# psoc4200bl register map
Vendor: Cypress Semiconductor; Series: PSoC4200BL; File version: 1.0
CPU: CM0 r0p1, little endian, no MPU, no FPU, 2 interrupt priority bits
Registers are 32-bit, read-write, reset 0x0 unless marked. A register's access mark holds for its fields unless they carry their own. Offsets are from the block's base; [hi:lo] are bit positions; lines under a group give offsets from that group; {n}, {i} and the like mark numbered series; <NAME> marks a mode.

## BLE (part 4 of 5) — Bluetooth Low Energy Subsystem
Base 0x402E0000
0x1000 BLELL group — Bluetooth Low Energy Link Layer
  0x120 NEXT_CE_INSTANT ro — Next connection event instant
    [15:0] NEXT_CE_INSTANT — 16-bit internal reference clock value at which the next connection event will occur on a connection. The connection index register must be programmed with index of the connection, before reading the register.
  0x124 CONN_CE_COUNTER ro — connection event counter
    [15:0] CONNECTION_EVENT_COUNTER — This is the free running counter, connEventCounter as defined by Bluetooth spec. Firmware will read the instantaneous Event counter from this register, during connection update and channel map update procedure. Firmware will use this value to calculate the instant from which the new parameters (for connection update and channel map update) will be effective.
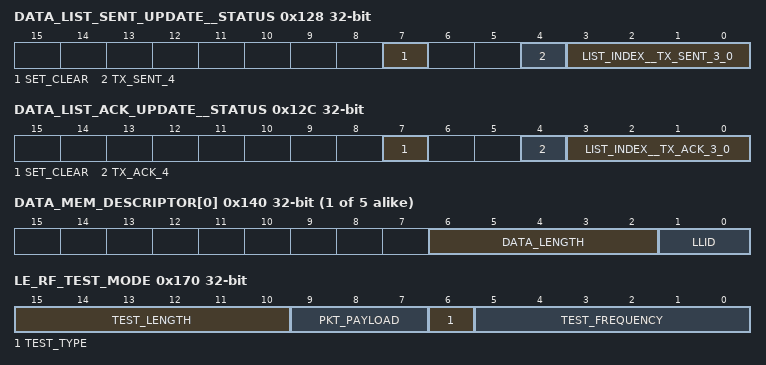
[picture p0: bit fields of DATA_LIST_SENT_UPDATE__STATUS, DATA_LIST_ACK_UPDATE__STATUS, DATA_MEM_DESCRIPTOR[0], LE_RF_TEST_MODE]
  0x128 DATA_LIST_SENT_UPDATE__STATUS — data list sent update and status
    [7] SET_CLEAR wo — Write: Used to set the SENT bit in hardware for the selected packet buffer. 1 - packet queued When firmware has a packet to send, firmware first loads the next available packet buffer. Then the hardware SENT bit is set by writing 1 to this bit field along with the list_index field that identified the buffer index. This indicates that a packet has been queued in the data buffer for sending. This packet is now ready to be transmitted. The SENT bit in hardware is cleared by hardware only when it has received an acknowledgement from the remote device. Firmware typically does not clear the bit. However, It only clears the bit on its own if it needs to 'flush' a packet from the buffer, without waiting to receive acknowledgement from the remote device, firmware clears BIT7 along with the list_index specified.
    [4] TX_SENT_4 ro — Read: Reads TX_SENT[4]. The bits in this field indicate the status of the SENT bit in the hard-ware for each packet buffer. The bit values are 1 - queued 0 - no packet / packet ack received by hardware Example1: If the read value is : 0x03, then packets in buffer 0 and buffer 1 are in the queue to be transmitted. All the other FIFOs are empty or hardware has cleared them after receiving acknowledgement. NOTE: The SENT status bit and ACK status bit have to be taken together to understand the meaning of packet status. The table below describes how the two bits are sequentially updated by either hardware/firmware to complete one data transmission. SENT ACK Description 0 0 Buffer is empty. No packet is queued in the buffer 1 0 Packet is queued by firmware. 1 1 Packet is transmitted by hardware. Hardware is waiting for acknowledgement. 0 1 Hardware has received ACK. Firmware has not yet processed the ACK. 0 0 Firmware has processed the ack. The buffer is again empty.
    [3:0] LIST_INDEX__TX_SENT_3_0 — Write:Indicates the buffer index for which the SENT bit is being updated by firmware. The default number of buffers in the IP is 5. The index range is 0-4. Read: Reads TX_SENT[3:0]. The bits in this field indicate the status of the SENT bit in the hard-ware for each packet buffer. The bit values are 1 - queued 0 - no packet / packet ack received by hardware Example1: If the read value is : 0x03, then packets in buffer 0 and buffer 1 are in the queue to be transmitted. All the other FIFOs are empty or hardware has cleared them after receiving acknowledgement.
  0x12C DATA_LIST_ACK_UPDATE__STATUS — data list ack update and status
    [7] SET_CLEAR wo — Write: Firmware uses the field to clear and ACK bit in the hardware to indicate that the acknowledgement for the transmit packet has been received and processed by firmware. Firmware clears the ACK bit in the hardware by writing in this register only after the acknowledgement is processed successfully by firmware. For clearing ack for a packet transmitted in fifo-index : '3', firm-ware will write '3' in the 'list-index' field and set this bit (BIT7) to 0. This is the indication that the corresponding packet buffer identi-fied by List-Index is cleared of previous transmission and can be re-used for another packet from now on. The ACK bit in hardware is set by hardware when it has success-fully transmitted a packet.
    [4] TX_ACK_4 ro — Reads TX_ACK[4] If a particular bit is set, then the packet in the selected buffer has been transmitted (at least once) by the hardware and hardware is waiting for acknowledgement. Example1 : If the read value is : 0x03, then packets in FIFO-0 and FIFO-1 are acknowledged by the remote device. These acknowledgements are pending to be processed by firmware. Example2 : If the read value is : 0x02, then packet FIFO-1 is acknowledged by the remote device. This acknowledgement is pending to be processed by firmware. NOTE: The SENT status bit and ACK status bit have to be taken together to understand the meaning of packet status. The table below describes how the two bits are sequentially updated by either hardware/firmware to complete one data transmission. SENT ACK Description 0 0 Buffer is empty. No packet is queued in the buffer 1 0 Packet is queued by firmware. 1 1 Packet is transmitted by hardware. Hardware is waiting for acknowledgement. 0 1 Hardware has received ACK. Firmware has not yet processed the ACK. 0 0 Firmware has processed the ack. The buffer is again empty.
    [3:0] LIST_INDEX__TX_ACK_3_0 — Write: Indicates the buffer index for which the ACK bit is being updated by firmware. The default number of buffers in the IP is 5. The index range is 0-4. Read: Reads TX_ACK[3:0] If a particular bit is set, then the packet in the selected buffer has been transmitted (at least once) by the hardware and hardware is waiting for acknowledgement. Example1 : If the read value is : 0x03, then packets in FIFO-0 and FIFO-1 are acknowledged by the remote device. These acknowledgements are pending to be processed by firmware. Example2 : If the read value is : 0x02, then packet FIFO-1 is acknowledged by the remote device. This acknowledgement is pending to be processed by firmware.
  {0x140+4j} DATA_MEM_DESCRIPTOR[{j}] (j=0..4) — Data buffer descriptor 0 to 4
    [6:2] DATA_LENGTH — This field indicates the length of the data packet. Range 0x0 to 0xF.
    [1:0] LLID
  0x160 WINDOW_WIDEN_INTVL reset 0xA — Window widen for interval
    [11:0] WINDOW_WIDEN_INTVL — This value defines the increased listening time for the slave. The window widening shall be smaller than ((connInterval/2)-T_IFS us) This value is calculated by firmware based on the drift, the connec-tion interval value. The value is the unit widening value for one con-nection interval duration. In case of slave latency, this value is accu-mulated till the next anchor point at which the slave will listen.
  0x164 WINDOW_WIDEN_WINOFF reset 0xA — Window widen for offset
    [11:0] WINDOW_WIDEN_WINOFF — This field stores the additional number of microseconds the slave must extend its listening window to listen for a master packet. This value is calculated based on the window offset value. This is used at connection setup directly. During connection setup, this value is added with window_widen_intvl register value to calculate the win-dow widening size.
  0x170 LE_RF_TEST_MODE — Direct Test Mode control
    [15:10] TEST_LENGTH
    [9:7] PKT_PAYLOAD
    [6] TEST_TYPE — 1 - DTM test ON 0 - DTM test OFF
    [5:0] TEST_FREQUENCY — N = (F - 2402) / 2 Range: 0x00 - 0x27. Frequency Range : 2402 MHz to 2480 MHz
  0x174 DTM_RX_PKT_COUNT ro — Direct Test Mode receive packet count
    [15:0] RX_PACKET_COUNT — Number of packets received in receive test mode.
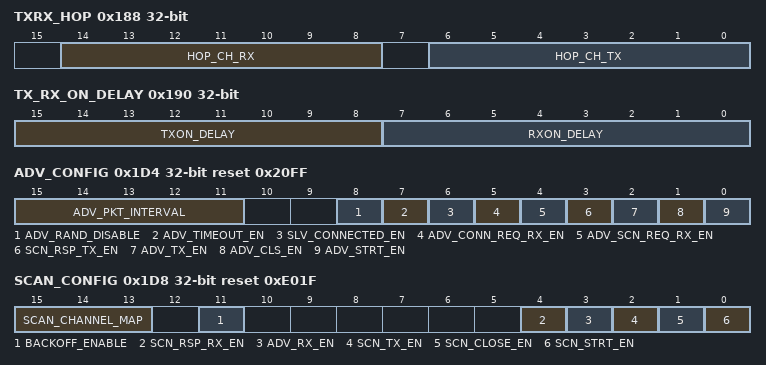
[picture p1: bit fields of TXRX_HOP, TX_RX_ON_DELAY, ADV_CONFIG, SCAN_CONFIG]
  0x188 TXRX_HOP ro — Channel Address register
    [14:8] HOP_CH_RX — Receive channel index. Channel index on which previous packet is received.
    [6:0] HOP_CH_TX — Transmit channel index. Channel index on which previous packet is transmitted.
  0x190 TX_RX_ON_DELAY — Transmit/Receive data delay
    [15:8] TXON_DELAY — Transmit delay - Delay from start of transmit to transmission of first bit on air. It is used to control the T_IFS. The delay is in resolution of 1 microsecond.
    [7:0] RXON_DELAY — Receive delay - Delay from start of receive to expected first bit of receive packet at the controller. Used to control the turn on time of radio to optimize on power. The delay is in resolution of 1 microsecond.
  0x1C0 DEV_PUB_ADDR_L reset 0x3412 — Device public address lower register
    [15:0] DEV_PUB_ADDR_L — Lower 16 bit of 48-bit public address of the device.
  0x1C4 DEV_PUB_ADDR_M reset 0x56 — Device public address middle register
    [15:0] DEV_PUB_ADDR_M — Middle 16 bit of 48-bit public address of the device.
  0x1C8 DEV_PUB_ADDR_H — Device public address higher register
    [15:0] DEV_PUB_ADDR_H — Higher 16 bit of 48-bit public address of the device.
  0x1CC ADV_CH_TX_POWER reset 0x874F — Advetising channel transmit power
    [15:0] ADV_TRANSMIT_POWER — Size: 1 Octet (signed integer) Range: -20 <= N <= 10 Units: dBm Accuracy: +/- 4 dBm in general. In implementation this is a radio specific value.
  0x1D0 OFFSET_TO_FIRST_INSTANT reset 0x6
    [15:0] OFFSET_TO_FIRST_EVENT — The offset w.r.t the internal reference clock at which instant the first event occurs. This register will give flexibility to the firmware to position the con-nection at a desired point with respect to the internal free running clock. It is optional to be updated by firmware. This is not updated in the current firmware.
  0x1D4 ADV_CONFIG reset 0x20FF — Advertiser configuration register
    [15:11] ADV_PKT_INTERVAL — Time between the beginning of two consecutive advertising PDU's. Time = N * 0.625 msec Time Range: <=10msec.
    [8] ADV_RAND_DISABLE — Disable randomization of adv interval. When disabled, interval is same as programmed in adv_interval register.
    [7] ADV_TIMEOUT_EN — Enable adv_timeout interrupt. Applicable in adv_direct_ind advertising.
    [6] SLV_CONNECTED_EN — Enable slave connected interrupt.
    [5] ADV_CONN_REQ_RX_EN — Enable connect request packet received interrupt.
    [4] ADV_SCN_REQ_RX_EN — Enable scan request packet received interrupt.
    [3] SCN_RSP_TX_EN — Enable scan response packet transmitted interrupt.
    [2] ADV_TX_EN — Enable adv packet transmitted interrupt.
    [1] ADV_CLS_EN — Enable advertising event stop interrupt.
    [0] ADV_STRT_EN — Enable advertising event start interrupt.
  0x1D8 SCAN_CONFIG reset 0xE01F — Scan configuration register
    [15:13] SCAN_CHANNEL_MAP — Advertising channels that are enabled for scanning operation. Bit 15: setting 1 - enables channel 39 for use. Bit 14: setting 1 - enables channel 38 for use. Bit 13: setting 1 - enables channel 37 for use.
    [11] BACKOFF_ENABLE — Enable random backoff feature in scanner. 1 - enable 0 - disable
    [4] SCN_RSP_RX_EN — Enable scan_rsp packet received interrupt .
    [3] ADV_RX_EN — Enable adv packet received interrupt .
    [2] SCN_TX_EN — Enable scan request packet transmitted interrupt.
    [1] SCN_CLOSE_EN — Enable scan event close interrupt.
    [0] SCN_STRT_EN — Enable scan event start interrupt.
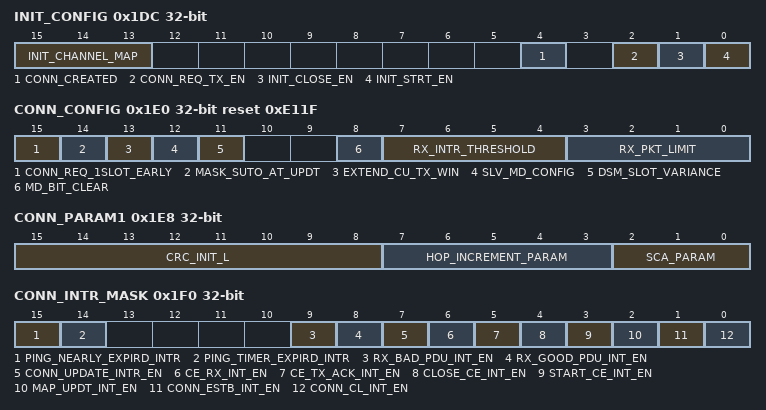
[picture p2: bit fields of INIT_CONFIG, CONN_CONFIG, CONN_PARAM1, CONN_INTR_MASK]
  0x1DC INIT_CONFIG — Initiator configuration register
    [15:13] INIT_CHANNEL_MAP — Advertising channels that are enabled for initiator scanning operation. Bit 15: setting 1 - enables channel 39 for use. Bit 14: setting 1 - enables channel 38 for use. Bit 13: setting 1 - enables channel 37 for use.
    [4] CONN_CREATED — Enable master connection created interrupt
    [2] CONN_REQ_TX_EN — Enables connection request packet transmission start interrupt.
    [1] INIT_CLOSE_EN — Enable Initiator event close interrupt.
    [0] INIT_STRT_EN — Enable Initiator event start interrupt.
  0x1E0 CONN_CONFIG reset 0xE11F — Connection configuration register
    [15] CONN_REQ_1SLOT_EARLY — This bit is used to enable extension of the Conn Request to arbiter to 1 slot early. When enabled the request length is 2 slots. 1 - Enable 0 - Disable
    [14] MASK_SUTO_AT_UPDT — This bit is used to enable/disable masking of internal hardware supervision timeout trigger when switching from old connection parameters to new parameters. 1 - Enable 0 - Disable
    [13] EXTEND_CU_TX_WIN — This bit is used to enable/disable extending the additional rx window on slave side during connection update in event of packet miss at the update instant. 1 - Enable 0 - Disable
    [12] SLV_MD_CONFIG — This bit is set to configure the MD bit control when IUT is in slave role. 1 - MD bit will be decided on packet pending status 0 - MD bit will be decided on packet queued in next buffer status This bit has effect only when 'CONN_CONFIG.md_bit_ctr' bit is not set .
    [11] DSM_SLOT_VARIANCE — This bit configures the DSM slot counting mode. 0 - The DSM slot count variance with respect to actual time is less than 1 slot 1 - The DSM slot count variance with respect to actual time is more than 1 slot &less that 2 slots
    [8] MD_BIT_CLEAR — This register field indicates whether the MD (More Data) bit needs to be controlled by 'software' or, 'hardware and soft-ware logic combined'. 1 - MD bit is exclusively controlled by software, ie based on status of CE_CNFG_STS_REGISTER[6] - md bit. 0 - MD Bit in the transmitted pdu is controlled by software and hardware logic. MD bit is set in transmitted packet, only if the software has set the md bit in CE_CNFG_STS_REGISTER[6] and either of the following conditions is true, a) If there are packets queued for transmission. b) If there is an acknowledgement awaited from the remote side for the packet transmitted.
    [7:4] RX_INTR_THRESHOLD — This register field allows setting a threshold for the packet received interrupt to the firmware. For example if the value programmed is 0x2 - then HW will generate interrupt only on receiving the second packet. In any case if the received number of packets in a conn event is less than the threshold or there are still packets (less than threshold) pending in the Rx FIFO, HW will generate the interrupt at the ce_close. Min value possible is 1. Max value depends on the Rx FIFO capacity.
    [3:0] RX_PKT_LIMIT — Defines a limit for the number of Rx packets that can be re-ceived by the LLH. Default maximum value is 0xF.Minimum value shall be '1' or no packet will be stored in the Rx FIFO.
  0x1E4 CONN_CH_TX_POWER — Connection channel transmit power
    [15:0] CONNCH_TRANSMIT_POWER — Transmit power to be used for all packets transmitted on the connection channel.
  0x1E8 CONN_PARAM1 — Connection parameter 1
    [15:8] CRC_INIT_L — This field defines the lower byte (7:0) of the CRC initialization vector.
    [7:3] HOP_INCREMENT_PARAM — Hop increment for connection channel.
    [2:0] SCA_PARAM — Sleep Clock Accuracy
  0x1EC CONN_PARAM2 — Connection parameter 2
    [15:0] CRC_INIT_H — This field defines the upper two bytes (23:8) of the CRC initialization vector.
  0x1F0 CONN_INTR_MASK — Connection Interrupt mask
    [15] PING_NEARLY_EXPIRD_INTR — If this bit is set ping timer nearly expired interrupt is enabled
    [14] PING_TIMER_EXPIRD_INTR — If this bit is set ping timer expired interrupt is enabled.
    [9] RX_BAD_PDU_INT_EN — If this bit is set packet receive bad pdu interrupt is enabled. Effective only when bit 6 is set.
    [8] RX_GOOD_PDU_INT_EN — If this bit is set packet receive good pdu interrupt is enabled. Effective only when bit 6 is set.
    [7] CONN_UPDATE_INTR_EN — If this bit is set connection update interrupt is enabled.
    [6] CE_RX_INT_EN — If this bit is set interrupt is enabled for reception of packet in a connection event.
    [5] CE_TX_ACK_INT_EN — If this bit is set transmission acknowledgement interrupt is enabled: This interrupt is generated to indicate to the firmware that a non-empty packet transmitted is successfully acknowledged by the remote device. For negative acknowledgements from remote device, this interrupt indication is not generated.
    [4] CLOSE_CE_INT_EN — If this bit is set connection event closed interrupt is enabled.
    [3] START_CE_INT_EN — If this bit is set connection event start interrupt is enabled
    [2] MAP_UPDT_INT_EN — If this bit is set, channel map update interrupt is enabled.
    [1] CONN_ESTB_INT_EN — If this bit is set connection establishment interrupt is enabled.
    [0] CONN_CL_INT_EN — If this bit is set connection closed interrupt is enabled.
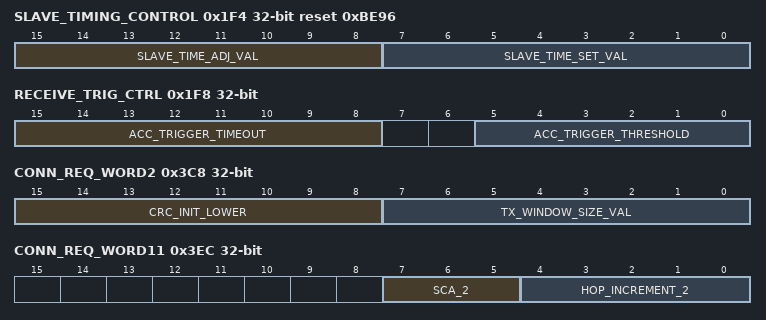
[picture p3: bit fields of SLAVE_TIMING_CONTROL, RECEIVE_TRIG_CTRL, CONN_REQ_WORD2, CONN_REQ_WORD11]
  0x1F4 SLAVE_TIMING_CONTROL reset 0xBE96
    [15:8] SLAVE_TIME_ADJ_VAL — Timing adjust value. The internal micro second counter is adjusted to this value whenever slave receives a good access address match at connection anchor point. This will ensure the slave gets synchronized to master timing.
    [7:0] SLAVE_TIME_SET_VAL — Programmable adjust value to the clock counter when slave is connected
  0x1F8 RECEIVE_TRIG_CTRL — Receive trigger control
    [15:8] ACC_TRIGGER_TIMEOUT — If access address match does not occur then within this time from the start of receive operation, the receive operation times out and stops. An internal counter value of 1usec resolution is continuously compared with the value programmed. Max value :0xFF
    [5:0] ACC_TRIGGER_THRESHOLD — Access address match threshold value. Number of bits of ac-cess address that should match with the expected access ad-dress to trigger an access code match. Max value : 32 (for 32-bit access address) Lower values may be programmed for bad radios or channels but care must be taken to ensure there are no 'false' matches due to reduced number of bits required to match.
  0x258 DPLL_CONFIG reset 0x92E0 — DPLL & CY Correlator configuration register
    [15:0] DPLL_CORREL_CONFIG — If CY_CORREL_EN is 0: [2:0] Read pointer correction on DPLL overflow. Optimal setting is 0x4. [6:4] Minimum distance from Rd ptr to Wr ptr to start read in DPLL. Optimal setting is 0x6. [11:8] Sets lower water mark for DPLL. Optimal setting is 0x2. [15:12] Sets upper water mark for DPLL. Optimal setting is 0x9. If CY_CORREL_EN is 1: [11:0] CY correl Access address compare mask for LSB 12 bits. Ideal value is 0xFFF [15:12] CY correl maximum number of allowed mismatched bits in access address. Ideal value is 0x0.
  0x340 WHITELIST_BASE_ADDR — Whitelist base address
    [15:0] WL_BASE_ADDR — Device address values written to white list memory are written as 16-bit wide address.
  0x3A4 CONN_UPDATE_NEW_INTERVAL — Connection update new interval
    [15:0] CONN_UPDT_INTERVAL — This register will have the new connection interval that the hardware will use after the connection update instant. Before the instant, the connection interval in the register CONN_INTERVAL will be used by hardware.
  0x3A8 CONN_UPDATE_NEW_LATENCY — Connection update new latency
    [15:0] CONN_UPDT_SLV_LATENCY — This register will have the new slave latency parameter that the hardware will use after the connection update instant. Before the instant, the connection interval in the register SLAVE_LATENCY will be used by hardware.
  0x3AC CONN_UPDATE_NEW_SUP_TO — Connection update new supervision timeout
    [15:0] CONN_UPDT_SUP_TO — This register will have the new supervision timeout that the hardware will use after the connection update instant. Before the instant, the connection interval in the register SUP_TIMEOUT will be used by hardware.
  0x3B0 CONN_UPDATE_NEW_SL_INTERVAL — Connection update new Slave Latency X Conn interval Value
    [15:0] SL_CONN_INTERVAL_VAL — This register will have the new Slave Latency * Conn Interval value that the hardware will use after the connection update instant. Before the instant, the connection interval in the register SL_CONN_INTERVAL will be used by hardware.
  0x3C0 CONN_REQ_WORD0 — Connection request address word 0
    [15:0] ACCESS_ADDR_LOWER — This field defines the lower 16 bits of the access address that is to be sent in the connect request packet of the initiator.
  0x3C4 CONN_REQ_WORD1 — Connection request address word 1
    [15:0] ACCESS_ADDR_UPPER — This field defines the upper16 bits of the access address that is to be sent in the connect request packet of the initiator.
  0x3C8 CONN_REQ_WORD2 — Connection request address word 2
    [15:8] CRC_INIT_LOWER — This field defines the lower byte [7:0] of the CRC initialization value.
    [7:0] TX_WINDOW_SIZE_VAL — window_size along with the window_offset is used to calculate the first connection point anchor point for the master. This shall be a multiple of 1.25 ms in the range of 1.25 ms to the lesser of 10 ms and (connInterval - 1.25 ms). Values range from 0 to 10 ms.
  0x3CC CONN_REQ_WORD3 — Connection request address word 3
    [15:0] CRC_INIT_UPPER — This field defines the upper byte [23:8] of the CRC initialization value that is to be sent in the connect request packet of the initiator.
  0x3D0 CONN_REQ_WORD4 — Connection request address word 4
    [15:0] TX_WINDOW_OFFSET — This is used to determine the anchor point for the master transmission. Range: This shall be a multiple of 1.25 ms in the range of 0 ms to connInterval value.
  0x3D4 CONN_REQ_WORD5 — Connection request address word 5
    [15:0] CONNECTION_INTERVAL_VAL — The value configured in this register determines the spacing between the connection events. This shall be a multiple of 1.25 ms in the range of 7.5 ms to 4.0 s.
  0x3D8 CONN_REQ_WORD6 — Connection request address word 6
    [15:0] SLAVE_LATENCY_VAL — The value configured in this field defines the number of consecutive connection events that the slave device is not required to listen for master. The value of connSlaveLatency should not cause a Supervision Timeout. This shall be an integer in the range of 0 to ((connSupervision Timeout/connInterval)-1). connSlaveLatency shall also be less than 500.
  0x3DC CONN_REQ_WORD7 — Connection request address word 7
    [15:0] SUPERVISION_TIMEOUT_VAL — This field defines the maximum time between two received Data packet PDUs before the connection is considered lost. This shall be a multiple of 10 ms in the range of 100 ms to 32.0 s and it shall be larger than (1+connSlaveLatency)*connInterval.
  0x3E0 CONN_REQ_WORD8 — Connection request address word 8
    [15:0] DATA_CHANNELS_LOWER — This register field indicates which of the data channels are in use. This stores the information for the lower 16 (15:0) data channel indices. 1' indicates the corresponding data channel is used and '0' indicates the channel is unused.
  0x3E4 CONN_REQ_WORD9 — Connection request address word 9
    [15:0] DATA_CHANNELS_MID — This register field indicates which of the data channels are in use. This stores the information for the middle 16 (31:16) data channel indices. '1' indicates the corresponding data channel is used and '0' indicates the channel is unused.
  0x3E8 CONN_REQ_WORD10 — Connection request address word 10
    [4:0] DATA_CHANNELS_UPPER — This register field indicates which of the data channels are in use. This stores the information for the upper 5 (36:32) data channel indices. '1' indicates the corresponding data channel is used and '0' indicates the channel is unused.
  0x3EC CONN_REQ_WORD11 — Connection request address word 11
    [7:5] SCA_2 — This field defines the sleep clock accuracies given in ppm.
    [4:0] HOP_INCREMENT_2 — This field is used for the data channel selection process.
  0x400 PACKET_COUNTER0
    [15:0] PACKET_COUNTER_LOWER — Lower 16-bits of the packet counter value passed as part of Nonce for the packet to be encrypted.
  0x404 PACKET_COUNTER1
    [15:0] PACKET_COUNTER_MIDDLE — Middle 16-bits of the packet counter value passed as part of Nonce for the packet to be encrypted.
  0x408 PACKET_COUNTER2
    [7:0] PACKET_COUNTER_UPPER — Upper 8 bits of the packet counter value passed as part of Nonce for the packet to be encrypted.
  0x410 IV_MASTER0 — Master Initialization Vector 0
    [15:0] IV_MASTER_LOWER — This is the lower 16-bits of the IVm field, which contains the master's portion of the initialization vector.
  0x414 IV_MASTER1 — Master Initialization Vector 1
    [15:0] IV_MASTER_UPPER — This is the upper 16-bits of the IVm field, which contains the master's portion of the initialization vector.
  0x418 IV_SLAVE0 — Slave Initialization Vector 0
    [15:0] IV_SLAVE_LOWER — This is the lower 16-bits of the IVs field, which contains the slave's portion of the initialization vector.
  0x41C IV_SLAVE1 — Slave Initialization Vector 1
    [15:0] IV_SLAVE_UPPER — This is the upper 16-bits of the IVs field, which contains the slave's portion of the initialization vector.
  {0x420+4j} ENC_KEY[{j}] (j=0..7) wo — Encryption Key register 0-7
    [15:0] ENC_KEY — The encryption key / session key which is used in ECB encryption, CCM encryption and CCM decryption.
  {0x440+4j} DATA{j} (j=0..12) — Input / Output Data register
    [15:0] DATA{j} — Write: Bytes {2j+1} and {2j} of the input plain text to be encrypted. Read: Bytes {2j+1} and {2j} of the decrypted plain text/ encrypted text.
  0x474 DATA13 — Input / Output Data register
    [7:0] DATA13 — Write: Byte 26 of the input plain text to be encrypted. Read: Byte 26 of the decrypted plain text/ encrypted text.
  0x478 MIC_IN0 — MIC input register
    [15:0] MIC_IN_LOWER — This is the lower 16-bits of the MIC field used for CCM decryption.
  0x47C MIC_IN1 — MIC input register
    [15:0] MIC_IN_UPPER — This is the upper 16-bits of the MIC field used for CCM decryption.
  0x480 MIC_OUT0 ro — MIC output register
    [15:0] MIC_OUT_LOWER — This is the lower 16-bits of the MIC generated during CCM encryption.
  0x484 MIC_OUT1 ro — MIC output register
    [15:0] MIC_OUT_UPPER — This is the lower 16-bits of the MIC generated during CCM encryption.
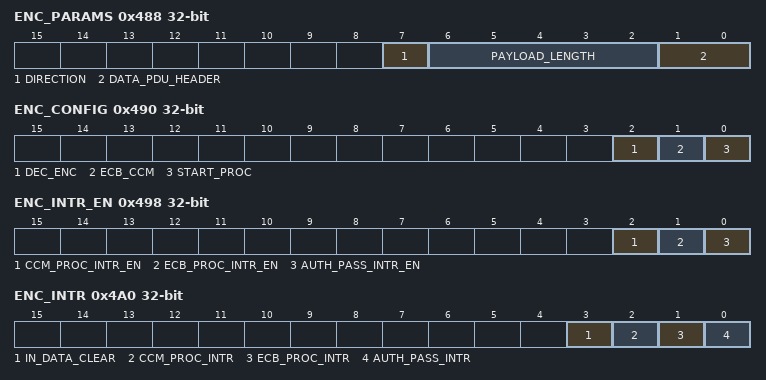
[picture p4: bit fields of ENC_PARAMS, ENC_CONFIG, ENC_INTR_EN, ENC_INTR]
  0x488 ENC_PARAMS — Encryption Parameter register
    [7] DIRECTION — The directionBit shall be set to '1' for Data Channel PDUs sent by the master and set to '0' for Data Channel PDUs sent by the slave.
    [6:2] PAYLOAD_LENGTH — Length of the input data.
    [1:0] DATA_PDU_HEADER — LLID of the packet.
  0x490 ENC_CONFIG — Encryption Configuration
    [2] DEC_ENC — Decryption/Encryption 0 - Encrypt 1 - Decrypt
    [1] ECB_CCM — 0 - CCM 1 - ECB
    [0] START_PROC — 1 Start the AES processing
  0x498 ENC_INTR_EN — Encryption Interrupt enable
    [2] CCM_PROC_INTR_EN — CCM processed interupt enable 0 - Disable 1 - Enable
    [1] ECB_PROC_INTR_EN — ECB processed interrupt enable 0 - Disable 1 - Enable
    [0] AUTH_PASS_INTR_EN — Authentication interrupt enable 0 - Disable 1 - Enable
  0x4A0 ENC_INTR — Encryption Interrupt status and clear register
    [3] IN_DATA_CLEAR wo — Clears the input data. Used for Zero padding of encryption for less than block sized data.
    [2] CCM_PROC_INTR — CCM processed interrupt. Writing 1 to this register clears the interrupt
    [1] ECB_PROC_INTR — ECB processed interrupt. Writing 1 to this register clears the interrupt.
    [0] AUTH_PASS_INTR — Authentication interrupt. 0x1- indicates MIC matched 0x0 -indicated MIC mismatched Writing 1 to this register clears the interrupt.
  0x600 CONN_TXMEM_BASE_ADDR — Connection TX memory base address
    [15:0] CONN_TX_MEM_BASE_ADDR — Data values written to Tx memory are written as 16-bit wide data.
  0x800 CONN_RXMEM_BASE_ADDR — Connection RX memory base address
    [15:0] CONN_RX_MEM_BASE_ADDR — Data values written to Rx memory are written as 16-bit wide data
  0xA04 PDU_RESP_TIMER — PDU response timer
    [15:0] PDU_RESP_TIME_VAL — This register is loaded with the count value to monitor the time to get a response for a PDU from peer device. Firmware starts the timer by issuing the command, RESP_TIMER_ON, after it has queued a PDU for transmission, that requires a response. If a response is received, firmware stops and clears the timer by issuing the command RESP_TIMER_OFF. If this timer expires, it results in hardware closing the connection and triggering a conn_closed interrupt. The discon_status field in the Connection status register is set with the appropriate reason. Units : Milliseconds. Resolution : 1.25 ms
  0xA08 NEXT_RESP_TIMER_EXP ro — Next response timeout instant
    [15:0] NEXT_RESPONSE_INSTANT — This field defines the clock instant at which the next PDU response timeout event will occur on a connection. This is with reference to the 16-bit internal reference clock.
  0xA0C NEXT_SUP_TO ro — Next supervision timeout instant
    [15:0] NEXT_TIMEOUT_INSTANT — This field defines the clock instant at which the next connection supervision timeout event will occur on a connection This is with reference to the 16-bit internal reference clock.
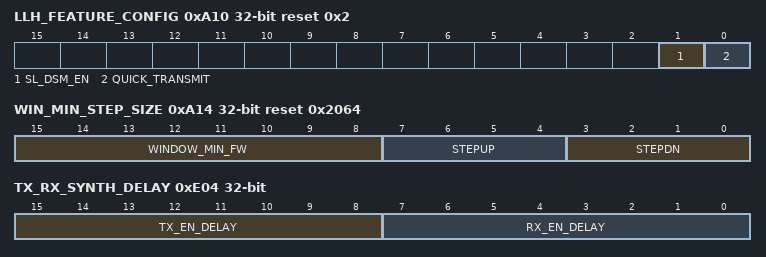
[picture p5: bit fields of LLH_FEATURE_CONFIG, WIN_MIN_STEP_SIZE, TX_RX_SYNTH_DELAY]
  0xA10 LLH_FEATURE_CONFIG reset 0x2 — Feature enable
    [1] SL_DSM_EN — Enable/Disable Slave Latency Period DSM.
    [0] QUICK_TRANSMIT — Quick transmit feature in slave latency is enabled by setting this bit. When slave latency is enabled, this feature enables the slave to transmit in the immediate connection interval, in case required, instead of waiting till the end of slave latency
  0xA14 WIN_MIN_STEP_SIZE reset 0x2064 — Window minimum step size
    [15:8] WINDOW_MIN_FW — Minimum window interval value programmed by firmware. While the slave receive window is decremented, the windows_min_fw sets the lowest value of the window widen value to ensure packets are not missed. The unit is in microseconds.
    [7:4] STEPUP — If packets are missed, the reference window is gradually increased by step up size, until it receives 2 consecutive good packets. The unit is in microseconds
    [3:0] STEPDN — After receiving 2 consecutive good packets the reference window is gradually decremented by step down size until it reaches window minimum. The unit is in microseconds
  0xA18 SLV_WIN_ADJ reset 0x10 — Slave window adjustment
    [10:0] SLV_WIN_ADJ — Window Adjust value. This value is added to the calculated slave window widening value to be used as final window widen value.
  0xA1C SL_CONN_INTERVAL — Slave Latency X Conn Interval Value
    [15:0] SL_CONN_INTERVAL_VAL — This field defines the (SL*CI) product for the ongoing connection. This value is used in calculation of next connection instant during slave latency.
  0xA20 LE_PING_TIMER_ADDR — LE Ping connection timer address
    [15:0] CONN_PING_TIMER_ADDR — The register used to configure the LE Au-thenticated payload Timeout (LE APTO) which is the Maximum amount of time specified between packets authenticated by a MIC. This value of ping timer is in the order of 10ms, valid range 0x1 ~ 0xFFFF
  0xA24 LE_PING_TIMER_OFFSET — LE Ping connection timer offset
    [15:0] CONN_PING_TIMER_OFFSET — The value of ping timer nearly expired offset in the order of 10ms, valid range 0x0 ~ 0xFFFF. This is the time period after which the ping timer nearly expired interrupt is generated.
  0xA28 LE_PING_TIMER_NEXT_EXP ro — LE Ping timer next expiry instant
    [15:0] CONN_PING_TIMER_NEXT_EXP — The value of ping timer next expiry instant in the terms of native clock value (least 16 bit value of the 17 bit ping counter). This together with CONN_PING_TIMER_NEXT_EXP_WRAP will provide the correct status of ping timer duration.
  0xA2C LE_PING_TIMER_WRAP_COUNT ro
    [15:0] CONN_SEC_CURRENT_WRAP — This register holds the current position of the Ping timer.
  0xE00 TX_EN_EXT_DELAY reset 0x5 — Transmit enable extension delay
    [4:0] TXEN_EXT_DELAY — Transmit enable extension delay. This is to extend the active state (high) of rif_tx_en signal after the last bit is sent out from LLH. The unit is in microsecond and the supported range is 00 - 31 us.
  0xE04 TX_RX_SYNTH_DELAY — Transmit/Receive enable delay
    [15:8] TX_EN_DELAY — The delay used to assert rif_tx_en exactly Tx_tRamp micro-seconds ahead of the first bit of the tx_data, which can be used to turn on the Radio transmitter. The value to be programmed to the Tx_en_delay [7:0] = tx_on_delay - Tx_tRamp tx_on_delay[7:0] = TX_RX_ON_DELAY[15:8]) Tx_tRamp = Radio transmitter ramp_up
    [7:0] RX_EN_DELAY — The delay used to assert rif_rx_en, Rx_tRamp micro-seconds, ahead of first bit of the expected rx_data, which can be used to turn on the Radio receiver. The value to be programmed to the Rx_en_delay [7:0] = rx_on_delay - Rx_tRamp rx_on_delay[7:0] = TX_RX_ON_DELAY[7:0]) Rx_tRamp = Radio receiver rampup time
